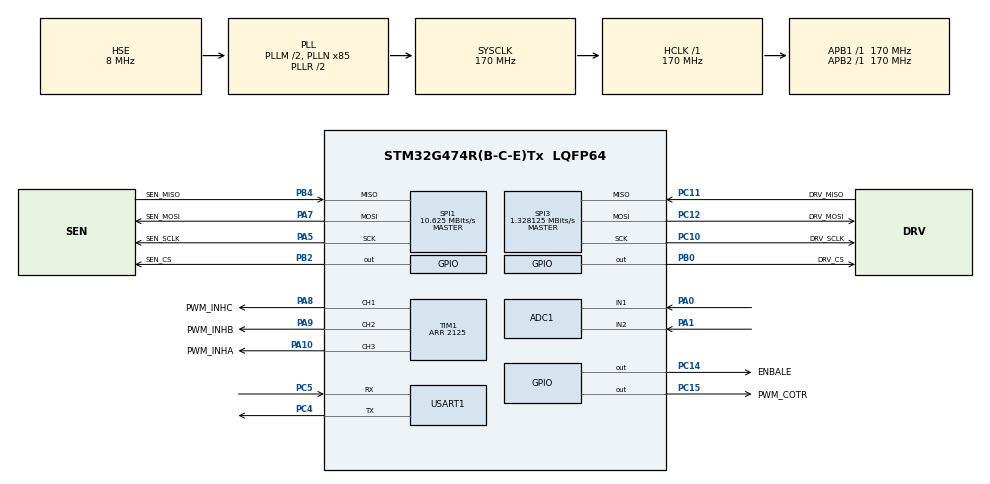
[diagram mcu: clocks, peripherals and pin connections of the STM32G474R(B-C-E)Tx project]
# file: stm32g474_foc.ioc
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ADC1.EnableInjectedConversion=ENABLE
ADC1.EnableRegularConversion=DISABLE
ADC1.ExternalTrigInjecConv=ADC_EXTERNALTRIGINJEC_T1_TRGO
ADC1.InjNumberOfConversion=2
ADC1.InjectedChannel-2\#ChannelInjectedConversion=ADC_CHANNEL_1
ADC1.InjectedChannel-3\#ChannelInjectedConversion=ADC_CHANNEL_1
ADC1.InjectedOffsetNumber-2\#ChannelInjectedConversion=ADC_OFFSET_NONE
ADC1.InjectedOffsetNumber-3\#ChannelInjectedConversion=ADC_OFFSET_NONE
ADC1.InjectedRank-2\#ChannelInjectedConversion=1
ADC1.InjectedRank-3\#ChannelInjectedConversion=2
ADC1.InjectedSamplingTime-2\#ChannelInjectedConversion=ADC_SAMPLETIME_6CYCLES_5
ADC1.InjectedSamplingTime-3\#ChannelInjectedConversion=ADC_SAMPLETIME_6CYCLES_5
ADC1.master=1
Mcu.Family=STM32G4
Mcu.Name=STM32G474R(B-C-E)Tx
Mcu.Package=LQFP64
NVIC.ADC1_2_IRQn=true\:1\:0\:true\:false\:true\:true\:true\:true
NVIC.PriorityGroup=NVIC_PRIORITYGROUP_4
NVIC.TIM1_TRG_COM_TIM17_IRQn=true\:0\:0\:false\:false\:true\:true\:true\:true
PA0.Mode=IN1-Single-Ended
PA0.Signal=ADC1_IN1
PA1.Mode=IN2-Single-Ended
PA1.Signal=ADC1_IN2
PA10.GPIO_Label=PWM_INHA
PA10.GPIO_Speed=GPIO_SPEED_FREQ_VERY_HIGH
PA10.Signal=S_TIM1_CH3
PA13.Mode=Serial_Wire
PA13.Signal=SYS_JTMS-SWDIO
PA14.Mode=Serial_Wire
PA14.Signal=SYS_JTCK-SWCLK
PA5.GPIO_Label=SEN_SCLK
PA5.GPIO_Speed=GPIO_SPEED_FREQ_VERY_HIGH
PA5.Mode=Full_Duplex_Master
PA5.Signal=SPI1_SCK
PA7.GPIO_Label=SEN_MOSI
PA7.GPIO_Speed=GPIO_SPEED_FREQ_VERY_HIGH
PA7.Mode=Full_Duplex_Master
PA7.Signal=SPI1_MOSI
PA8.GPIO_Label=PWM_INHC
PA8.GPIO_Speed=GPIO_SPEED_FREQ_VERY_HIGH
PA8.Signal=S_TIM1_CH1
PA9.GPIO_Label=PWM_INHB
PA9.GPIO_Speed=GPIO_SPEED_FREQ_VERY_HIGH
PA9.Signal=S_TIM1_CH2
PB0.GPIO_Label=DRV_CS
PB0.GPIO_Speed=GPIO_SPEED_FREQ_VERY_HIGH
PB0.Signal=GPIO_Output
PB2.GPIO_Label=SEN_CS
PB2.GPIO_Speed=GPIO_SPEED_FREQ_VERY_HIGH
PB2.Signal=GPIO_Output
PB4.GPIO_Label=SEN_MISO
PB4.GPIO_Speed=GPIO_SPEED_FREQ_VERY_HIGH
PB4.Mode=Full_Duplex_Master
PB4.Signal=SPI1_MISO
PC10.GPIO_Label=DRV_SCLK
PC10.GPIO_Speed=GPIO_SPEED_FREQ_VERY_HIGH
PC10.Mode=Full_Duplex_Master
PC10.Signal=SPI3_SCK
PC11.GPIO_Label=DRV_MISO
PC11.GPIO_Speed=GPIO_SPEED_FREQ_VERY_HIGH
PC11.Mode=Full_Duplex_Master
PC11.Signal=SPI3_MISO
PC12.GPIO_Label=DRV_MOSI
PC12.GPIO_Speed=GPIO_SPEED_FREQ_VERY_HIGH
PC12.Mode=Full_Duplex_Master
PC12.Signal=SPI3_MOSI
PC14-OSC32_IN.GPIO_Label=ENBALE
PC14-OSC32_IN.Signal=GPIO_Output
PC15-OSC32_OUT.GPIO_Label=PWM_COTR
PC15-OSC32_OUT.GPIO_Speed=GPIO_SPEED_FREQ_LOW
PC15-OSC32_OUT.Signal=GPIO_Output
PC4.Mode=Asynchronous
PC4.Signal=USART1_TX
PC5.Mode=Asynchronous
PC5.Signal=USART1_RX
PF0-OSC_IN.Mode=HSE-External-Oscillator
PF0-OSC_IN.Signal=RCC_OSC_IN
PF1-OSC_OUT.Mode=HSE-External-Oscillator
PF1-OSC_OUT.Signal=RCC_OSC_OUT
ProjectManager.HeapSize=0x200
ProjectManager.StackSize=0x400
ProjectManager.TargetToolchain=MDK-ARM V5.32
RCC.ADC12Freq_Value=170000000
RCC.ADC345Freq_Value=170000000
RCC.AHBFreq_Value=170000000
RCC.APB1Freq_Value=170000000
RCC.APB1TimFreq_Value=170000000
RCC.APB2Freq_Value=170000000
RCC.APB2TimFreq_Value=170000000
RCC.CortexFreq_Value=170000000
RCC.EXTERNAL_CLOCK_VALUE=12288000
RCC.HCLKFreq_Value=170000000
RCC.HSE_VALUE=8000000
RCC.HSI48_VALUE=48000000
RCC.HSI_VALUE=16000000
RCC.LSE_VALUE=32768
RCC.PLLM=RCC_PLLM_DIV2
RCC.PLLN=85
RCC.PLLSourceVirtual=RCC_PLLSOURCE_HSE
RCC.SYSCLKFreq_VALUE=170000000
RCC.SYSCLKSource=RCC_SYSCLKSOURCE_PLLCLK
RCC.USBFreq_Value=170000000
RCC.VCOOutputFreq_Value=340000000
SH.S_TIM1_CH1.0=TIM1_CH1,PWM Generation1 CH1
SH.S_TIM1_CH2.0=TIM1_CH2,PWM Generation2 CH2
SH.S_TIM1_CH3.0=TIM1_CH3,PWM Generation3 CH3
SPI1.BaudRatePrescaler=SPI_BAUDRATEPRESCALER_16
SPI1.CLKPhase=SPI_PHASE_2EDGE
SPI1.CalculateBaudRate=10.625 MBits/s
SPI1.DataSize=SPI_DATASIZE_16BIT
SPI1.Direction=SPI_DIRECTION_2LINES
SPI1.Mode=SPI_MODE_MASTER
SPI1.VirtualType=VM_MASTER
SPI3.BaudRatePrescaler=SPI_BAUDRATEPRESCALER_128
SPI3.CLKPhase=SPI_PHASE_2EDGE
SPI3.CalculateBaudRate=1.328125 MBits/s
SPI3.DataSize=SPI_DATASIZE_16BIT
SPI3.Direction=SPI_DIRECTION_2LINES
SPI3.Mode=SPI_MODE_MASTER
SPI3.VirtualType=VM_MASTER
TIM1.AutoReloadPreload=TIM_AUTORELOAD_PRELOAD_ENABLE
TIM1.Channel-PWM\ Generation1\ CH1=TIM_CHANNEL_1
TIM1.Channel-PWM\ Generation2\ CH2=TIM_CHANNEL_2
TIM1.Channel-PWM\ Generation3\ CH3=TIM_CHANNEL_3
TIM1.CounterMode=TIM_COUNTERMODE_CENTERALIGNED1
TIM1.OCFastMode_PWM-PWM\ Generation1\ CH1=TIM_OCFAST_ENABLE
TIM1.OCFastMode_PWM-PWM\ Generation2\ CH2=TIM_OCFAST_ENABLE
TIM1.OCFastMode_PWM-PWM\ Generation3\ CH3=TIM_OCFAST_ENABLE
TIM1.PeriodNoDither=2125
TIM1.PulseNoDither_1=1062
TIM1.PulseNoDither_2=1062
TIM1.PulseNoDither_3=1062
TIM1.RepetitionCounter=1
TIM1.TIM_MasterOutputTrigger=TIM_TRGO_UPDATE
USART1.VirtualMode-Asynchronous=VM_ASYNC
VP_SYS_VS_DBSignals.Mode=DisableDeadBatterySignals
board=custom

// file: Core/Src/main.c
/* USER CODE BEGIN Header */
/**
  ******************************************************************************
  * @file           : main.c
  * @brief          : Main program body
  ******************************************************************************
  * @attention
  *
  * Copyright (c) 2025 STMicroelectronics.
  * All rights reserved.
  *
  * This software is licensed under terms that can be found in the LICENSE file
  * in the root directory of this software component.
  * If no LICENSE file comes with this software, it is provided AS-IS.
  *
  ******************************************************************************
  */
/* USER CODE END Header */
#include "main.h"
#include "adc.h"
#include "spi.h"
#include "tim.h"
#include "usart.h"
#include "gpio.h"

/* USER CODE BEGIN Includes */
#include "user_main.h"
/* USER CODE END Includes */

void SystemClock_Config(void);

int main(void)
{

  /* MCU Configuration--------------------------------------------------------*/

  /* Reset of all peripherals, Initializes the Flash interface and the Systick. */
  HAL_Init();

  /* Configure the system clock */
  SystemClock_Config();

  /* Initialize all configured peripherals */
  MX_GPIO_Init();
  MX_ADC1_Init();
  MX_SPI1_Init();
  MX_SPI3_Init();
  MX_TIM1_Init();
  MX_USART1_UART_Init();
  /* USER CODE BEGIN 2 */
  User_Setup();
  /* USER CODE END 2 */

  /* Infinite loop */
  while (1)
  {

    /* USER CODE BEGIN 3 */
    User_Loop();
  }
  /* USER CODE END 3 */
}

void SystemClock_Config(void)
{
  RCC_OscInitTypeDef RCC_OscInitStruct = {0};
  RCC_ClkInitTypeDef RCC_ClkInitStruct = {0};

  /** Configure the main internal regulator output voltage
  */
  HAL_PWREx_ControlVoltageScaling(PWR_REGULATOR_VOLTAGE_SCALE1_BOOST);

  /** Initializes the RCC Oscillators according to the specified parameters
  * in the RCC_OscInitTypeDef structure.
  */
  RCC_OscInitStruct.OscillatorType = RCC_OSCILLATORTYPE_HSE;
  RCC_OscInitStruct.HSEState = RCC_HSE_ON;
  RCC_OscInitStruct.PLL.PLLState = RCC_PLL_ON;
  RCC_OscInitStruct.PLL.PLLSource = RCC_PLLSOURCE_HSE;
  RCC_OscInitStruct.PLL.PLLM = RCC_PLLM_DIV2;
  RCC_OscInitStruct.PLL.PLLN = 85;
  RCC_OscInitStruct.PLL.PLLP = RCC_PLLP_DIV2;
  RCC_OscInitStruct.PLL.PLLQ = RCC_PLLQ_DIV2;
  RCC_OscInitStruct.PLL.PLLR = RCC_PLLR_DIV2;
  if (HAL_RCC_OscConfig(&RCC_OscInitStruct) != HAL_OK)
  {
    Error_Handler();
  }

  /** Initializes the CPU, AHB and APB buses clocks
  */
  RCC_ClkInitStruct.ClockType = RCC_CLOCKTYPE_HCLK|RCC_CLOCKTYPE_SYSCLK
                              |RCC_CLOCKTYPE_PCLK1|RCC_CLOCKTYPE_PCLK2;
  RCC_ClkInitStruct.SYSCLKSource = RCC_SYSCLKSOURCE_PLLCLK;
  RCC_ClkInitStruct.AHBCLKDivider = RCC_SYSCLK_DIV1;
  RCC_ClkInitStruct.APB1CLKDivider = RCC_HCLK_DIV1;
  RCC_ClkInitStruct.APB2CLKDivider = RCC_HCLK_DIV1;

  if (HAL_RCC_ClockConfig(&RCC_ClkInitStruct, FLASH_LATENCY_4) != HAL_OK)
  {
    Error_Handler();
  }
}

void Error_Handler(void)
{
  __disable_irq();
  while (1)
  {
  }
}
